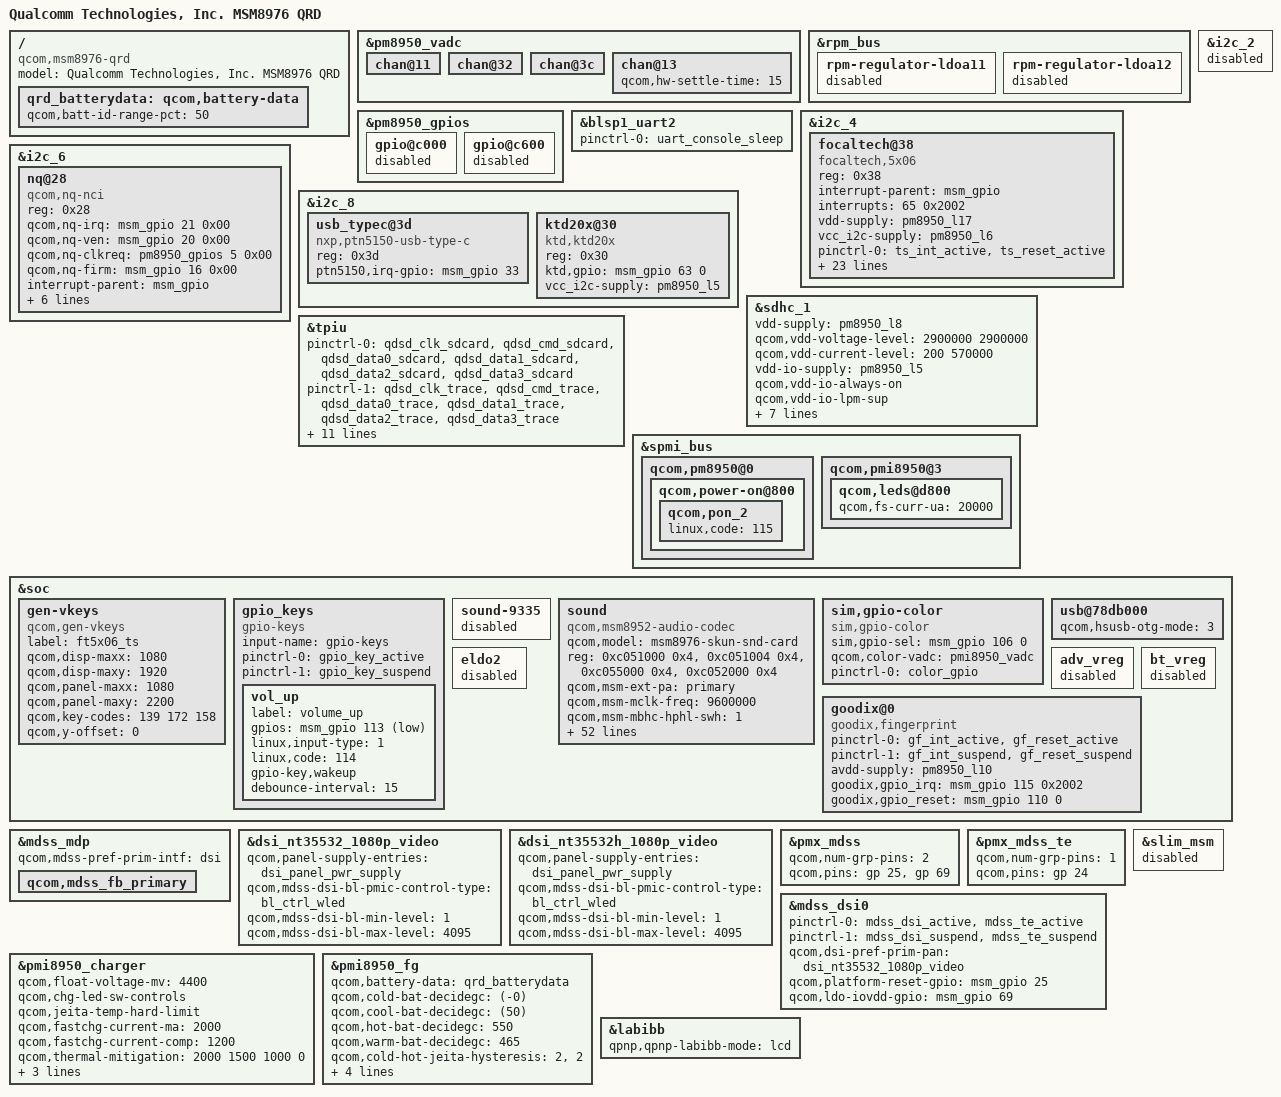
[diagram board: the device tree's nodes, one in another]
/*
 * Copyright (c) 2015, The Linux Foundation. All rights reserved.
 *
 * This program is free software; you can redistribute it and/or modify
 * it under the terms of the GNU General Public License version 2 and
 * only version 2 as published by the Free Software Foundation.
 *
 * This program is distributed in the hope that it will be useful,
 * but WITHOUT ANY WARRANTY; without even the implied warranty of
 * MERCHANTABILITY or FITNESS FOR A PARTICULAR PURPOSE.  See the
 * GNU General Public License for more details.
 */

#include "msm8976-camera-sensor-qrd.dtsi"

/ {
	model = "Qualcomm Technologies, Inc. MSM8976 QRD";
	compatible = "qcom,msm8976-qrd", "qcom,msm8976", "qcom,qrd";
};

&pm8950_vadc {
	chan@11 {
		/delete-property/ qcom,vadc-thermal-node;
	};
	chan@32 {
		/delete-property/ qcom,vadc-thermal-node;
	};
	chan@3c {
		/delete-property/ qcom,vadc-thermal-node;
	};
	chan@13 {
		/delete-property/ qcom,vadc-thermal-node;
	};
};

&rpm_bus {
	rpm-regulator-ldoa11 {
                status = "disabled";
	};

	rpm-regulator-ldoa12 {
                status = "disabled";
	};
};

&pm8950_gpios {
	gpio@c000 {
		status = "disabled";
	};

	gpio@c600 {
		status = "disabled";
	};
};

&pm8950_vadc {
	chan@13 {
		qcom,hw-settle-time = <15>;
	};
};

&blsp1_uart2 {
	status = "ok";
	pinctrl-names = "default";
	pinctrl-0 = <&uart_console_sleep>;
};

&i2c_2 { /* BLSP1 QUP2 */
	status = "disabled";
};

&i2c_4 { /* BLSP1 QUP4 */
        focaltech@38 {
                compatible = "focaltech,5x06";
                reg = <0x38>;
                interrupt-parent = <&msm_gpio>;
                interrupts = <65 0x2002>;
                vdd-supply = <&pm8950_l17>;
                vcc_i2c-supply = <&pm8950_l6>;
                /* pins used by touchscreen */
                pinctrl-names = "pmx_ts_active","pmx_ts_suspend","pmx_ts_release";
                pinctrl-0 = <&ts_int_active &ts_reset_active>;
                pinctrl-1 = <&ts_int_suspend &ts_reset_suspend>;
                pinctrl-2 = <&ts_release>;
                focaltech,name = "ft5336";
                focaltech,family-id = <0x06>;
                focaltech,reset-gpio = <&msm_gpio 64 0x0>;
                focaltech,irq-gpio = <&msm_gpio 65 0x2008>;
                focaltech,display-coords = <0 0 1080 1920>;
                focaltech,panel-coords = <0 0 1080 2200>;
                focaltech,button-map= <139 102 158>;
                focaltech,no-force-update;
                focaltech,i2c-pull-up;
                focaltech,group-id = <1>;
                focaltech,hard-reset-delay-ms = <20>;
                focaltech,soft-reset-delay-ms = <200>;
                focaltech,num-max-touches = <10>;
                focaltech,fw-delay-aa-ms = <30>;
                focaltech,fw-delay-55-ms = <30>;
                focaltech,fw-upgrade-id1 = <0x79>;
                focaltech,fw-upgrade-id2 = <0x08>;
                focaltech,fw-delay-readid-ms = <10>;
                focaltech,fw-delay-era-flsh-ms = <2000>;
                focaltech,fw-auto-cal;
                focaltech,ignore-id-check;
        };
};

&i2c_6 { /* BLSP2 QUP2 */
	nq@28 {
		compatible = "qcom,nq-nci";
		reg = <0x28>;
		qcom,nq-irq = <&msm_gpio 21 0x00>;
		qcom,nq-ven = <&msm_gpio 20 0x00>;
		qcom,nq-clkreq = <&pm8950_gpios 5 0x00>;
		qcom,nq-firm = <&msm_gpio 16 0x00>;
		interrupt-parent = <&msm_gpio>;
		qcom,clk-src = "BBCLK2";
		interrupts = <21 0>;
		interrupt-names = "nfc_irq";
		pinctrl-names = "nfc_active", "nfc_suspend";
		pinctrl-0 = <&nfc_int_active &nfc_disable_active>;
		pinctrl-1 = <&nfc_int_suspend &nfc_disable_suspend>;
		clocks = <&clock_gcc clk_bb_clk2_pin>;
		clock-names = "ref_clk";
	};
};

&i2c_8 { /* BLSP2 QUP4 */
	usb_typec@3d {
		compatible = "nxp,ptn5150-usb-type-c";
		reg = <0x3d>;
		ptn5150,irq-gpio = <&msm_gpio 33 0x2008>;
	};

        ktd20x@30 {
		compatible = "ktd,ktd20x";
		reg = <0x30>;
		ktd,gpio = <&msm_gpio 63 0>;
		vcc_i2c-supply = <&pm8950_l5>;
        };
};

&sdhc_1 {
	vdd-supply = <&pm8950_l8>;
	qcom,vdd-voltage-level = <2900000 2900000>;
	qcom,vdd-current-level = <200 570000>;

	vdd-io-supply = <&pm8950_l5>;
	qcom,vdd-io-always-on;
	qcom,vdd-io-lpm-sup;
	qcom,vdd-io-voltage-level = <1800000 1800000>;
	qcom,vdd-io-current-level = <200 325000>;

	pinctrl-names = "active", "sleep";
	pinctrl-0 = <&sdc1_clk_on &sdc1_cmd_on &sdc1_data_on &sdc1_rclk_on>;
	pinctrl-1 = <&sdc1_clk_off &sdc1_cmd_off &sdc1_data_off &sdc1_rclk_off>;

	qcom,nonremovable;

	status = "ok";
};

/* CoreSight */
&tpiu {
	pinctrl-names = "sdcard", "trace", "swduart",
			"swdtrc", "jtag", "spmi";
	/* NIDnT */
	pinctrl-0 = <&qdsd_clk_sdcard &qdsd_cmd_sdcard
		     &qdsd_data0_sdcard &qdsd_data1_sdcard
		     &qdsd_data2_sdcard &qdsd_data3_sdcard>;
	pinctrl-1 = <&qdsd_clk_trace &qdsd_cmd_trace
		     &qdsd_data0_trace &qdsd_data1_trace
		     &qdsd_data2_trace &qdsd_data3_trace>;
	pinctrl-2 = <&qdsd_cmd_swduart &qdsd_data0_swduart
		     &qdsd_data1_swduart &qdsd_data2_swduart
		     &qdsd_data3_swduart>;
	pinctrl-3 = <&qdsd_clk_swdtrc &qdsd_cmd_swdtrc
		     &qdsd_data0_swdtrc &qdsd_data1_swdtrc
		     &qdsd_data2_swdtrc &qdsd_data3_swdtrc>;
	pinctrl-4 = <&qdsd_cmd_jtag &qdsd_data0_jtag
		     &qdsd_data1_jtag &qdsd_data2_jtag
		     &qdsd_data3_jtag>;
	pinctrl-5 = <&qdsd_clk_spmi &qdsd_cmd_spmi
		     &qdsd_data0_spmi &qdsd_data3_spmi>;
};

&spmi_bus{
	qcom,pm8950@0 {
		qcom,power-on@800 {
			qcom,pon_2 {
				linux,code = <115>;
			};
		};
	};
	qcom,pmi8950@3 {
		qcom,leds@d800 {
			qcom,fs-curr-ua = <20000>;
		};
	};
};

&soc {

        gen-vkeys {
                compatible = "qcom,gen-vkeys";
                label = "ft5x06_ts";
                qcom,disp-maxx = <1080>;
                qcom,disp-maxy = <1920>;
                qcom,panel-maxx = <1080>;
                qcom,panel-maxy = <2200>;
                qcom,key-codes = <139 172 158>;
                qcom,y-offset = <0>;
        };

        gpio_keys {
                compatible = "gpio-keys";
                input-name = "gpio-keys";
                pinctrl-names = "tlmm_gpio_key_active","tlmm_gpio_key_suspend";
                pinctrl-0 = <&gpio_key_active>;
                pinctrl-1 = <&gpio_key_suspend>;

                vol_up {
                        label = "volume_up";
                        gpios = <&msm_gpio 113 0x1>;
                        linux,input-type = <1>;
                        linux,code = <114>;
                        gpio-key,wakeup;
                        debounce-interval = <15>;
                };
        };

        sound-9335 {
                status = "disabled";
        };

        sound {
                compatible = "qcom,msm8952-audio-codec";
                qcom,model = "msm8976-skun-snd-card";
                reg = <0xc051000 0x4>,
                      <0xc051004 0x4>,
                      <0xc055000 0x4>,
                      <0xc052000 0x4>;
                reg-names = "csr_gp_io_mux_mic_ctl",
                            "csr_gp_io_mux_spkr_ctl",
                            "csr_gp_io_lpaif_pri_pcm_pri_mode_muxsel",
                            "csr_gp_io_mux_quin_ctl";

                qcom,msm-ext-pa = "primary";
                qcom,msm-mclk-freq = <9600000>;
                qcom,msm-mbhc-hphl-swh = <1>;
                qcom,msm-mbhc-gnd-swh = <0>;
                qcom,msm-hs-micbias-type = "internal";
                qcom,msm-micbias1-ext-cap;
                qcom,audio-routing =
                        "RX_BIAS", "MCLK",
                        "SPK_RX_BIAS", "MCLK",
                        "INT_LDO_H", "MCLK",
                        "MIC BIAS External", "Handset Mic",
                        "MIC BIAS Internal2", "Headset Mic",
                        "MIC BIAS External", "Secondary Mic",
                        "AMIC1", "MIC BIAS External",
                        "AMIC2", "MIC BIAS Internal2",
                        "AMIC3", "MIC BIAS External";
                qcom,msm-gpios =
                        "pri_i2s";
                qcom,pinctrl-names =
                        "all_off",
                        "pri_i2s_act";
                pinctrl-names =
                        "all_off",
                        "pri_i2s_act";
                pinctrl-0 = <&cdc_pdm_lines_sus &cdc_pdm_lines_2_sus>;
                pinctrl-1 = <&cdc_pdm_lines_act &cdc_pdm_lines_2_act>;
                asoc-platform = <&pcm0>, <&pcm1>, <&pcm2>, <&voip>, <&voice>,
                                <&loopback>, <&compress>, <&hostless>,
                                <&afe>, <&lsm>, <&routing>, <&lpa>,
                                <&voice_svc>;
                asoc-platform-names = "msm-pcm-dsp.0", "msm-pcm-dsp.1",
                                "msm-pcm-dsp.2", "msm-voip-dsp",
                                "msm-pcm-voice", "msm-pcm-loopback",
                                "msm-compress-dsp", "msm-pcm-hostless",
                                "msm-pcm-afe", "msm-lsm-client",
                                "msm-pcm-routing", "msm-pcm-lpa",
                                "msm-voice-svc";
                asoc-cpu = <&dai_pri_auxpcm>, <&dai_hdmi>,
                                <&dai_mi2s0>, <&dai_mi2s1>, <&dai_mi2s2>,
                                <&dai_mi2s3>, <&dai_mi2s5>, <&dai_mi2s6>,
                                <&sb_0_rx>, <&sb_0_tx>, <&sb_1_rx>, <&sb_1_tx>,
                                <&sb_3_rx>, <&sb_3_tx>, <&sb_4_rx>, <&sb_4_tx>,
                                <&bt_sco_rx>, <&bt_sco_tx>, <&int_fm_rx>,
                                <&int_fm_tx>, <&afe_pcm_rx>, <&afe_pcm_tx>,
                                <&afe_proxy_rx>, <&afe_proxy_tx>,
                                <&incall_record_rx>, <&incall_record_tx>,
                                <&incall_music_rx>, <&incall_music_2_rx>;
                asoc-cpu-names = "msm-dai-q6-auxpcm.1", "msm-dai-q6-hdmi.8",
                                "msm-dai-q6-mi2s.0", "msm-dai-q6-mi2s.1",
                                "msm-dai-q6-mi2s.2", "msm-dai-q6-mi2s.3",
                                "msm-dai-q6-mi2s.5", "msm-dai-q6-mi2s.6",
                                "msm-dai-q6-dev.16384", "msm-dai-q6-dev.16385",
                                "msm-dai-q6-dev.16386", "msm-dai-q6-dev.16387",
                                "msm-dai-q6-dev.16390", "msm-dai-q6-dev.16391",
                                "msm-dai-q6-dev.16392", "msm-dai-q6-dev.16393",
                                "msm-dai-q6-dev.12288", "msm-dai-q6-dev.12289",
                                "msm-dai-q6-dev.12292", "msm-dai-q6-dev.12293",
                                "msm-dai-q6-dev.224", "msm-dai-q6-dev.225",
                                "msm-dai-q6-dev.241", "msm-dai-q6-dev.240",
                                "msm-dai-q6-dev.32771", "msm-dai-q6-dev.32772",
                                "msm-dai-q6-dev.32773", "msm-dai-q6-dev.32770";
                asoc-codec = <&stub_codec>, <&pm8950_cajon_dig>;
                asoc-codec-names = "msm-stub-codec.1", "cajon_codec";
        };

	sim,gpio-color {
                compatible = "sim,gpio-color";
                sim,gpio-sel = <&msm_gpio 106 0>;
                qcom,color-vadc = <&pmi8950_vadc>;

                pinctrl-names = "default";
                pinctrl-0 = <&color_gpio>;
        };
/* Disable following node as gpio-63 node would be controlled from KTD driver */
/*
        gpio-leds {
                compatible = "gpio-leds";
                status = "okay";

                disable_usb_led {
                        gpios = <&msm_gpio 63 0>;
                        label = "disable_usb_led";
                        linux,default-trigger = "default-on";
                        qcom,default-state = "on";
                        retain-state-suspended;
                };
        };
*/
        usb@78db000 {
                qcom,hsusb-otg-mode = <3>;/*Peripheral or Host mode */
        };

	eldo2 {
		status = "disabled";
	};

	adv_vreg {
		status = "disabled";
	};

	bt_vreg {
		status = "disabled";
	};
};

&soc {
        goodix@0 {
                compatible = "goodix,fingerprint";
                pinctrl-names = "pmx_gf_active", "pmx_gf_suspend";
                pinctrl-0 = <&gf_int_active &gf_reset_active>;
                pinctrl-1 = <&gf_int_suspend &gf_reset_suspend>;
                avdd-supply = <&pm8950_l10>;
                goodix,gpio_irq = <&msm_gpio 115 0x2002>;
                goodix,gpio_reset = <&msm_gpio 110 0>;
        };
};

#include "dsi-panel-nt35532-1080p-video.dtsi"
#include "dsi-panel-nt35532h-1080p-video.dtsi"

&mdss_mdp {
        qcom,mdss-pref-prim-intf = "dsi";
	qcom,mdss_fb_primary {
		/delete-property/ qcom,mdss-fb-splash-logo-enabled;
	};
};

&dsi_nt35532_1080p_video {
        qcom,panel-supply-entries = <&dsi_panel_pwr_supply>;
        qcom,mdss-dsi-bl-pmic-control-type = "bl_ctrl_wled";
        qcom,mdss-dsi-bl-min-level = <1>;
        qcom,mdss-dsi-bl-max-level = <4095>;
        //qcom,esd-check-enabled;
};

&dsi_nt35532h_1080p_video {
        qcom,panel-supply-entries = <&dsi_panel_pwr_supply>;
        qcom,mdss-dsi-bl-pmic-control-type = "bl_ctrl_wled";
        qcom,mdss-dsi-bl-min-level = <1>;
        qcom,mdss-dsi-bl-max-level = <4095>;
        //qcom,esd-check-enabled;
};

&pmx_mdss {
        qcom,num-grp-pins = <2>;
        qcom,pins = <&gp 25>, <&gp 69>;
};

&pmx_mdss_te {
        qcom,num-grp-pins = <1>;
        qcom,pins = <&gp 24>;
};

&mdss_dsi0 {
        pinctrl-names = "mdss_default", "mdss_sleep";
        pinctrl-0 = <&mdss_dsi_active &mdss_te_active>;
        pinctrl-1 = <&mdss_dsi_suspend &mdss_te_suspend>;
        qcom,dsi-pref-prim-pan = <&dsi_nt35532_1080p_video>;

        qcom,platform-reset-gpio = <&msm_gpio 25 0>;
        qcom,ldo-iovdd-gpio = <&msm_gpio 69 0>;
};


&pmi8950_charger {
        qcom,float-voltage-mv = <4400>;
        qcom,chg-led-sw-controls;
        /delete-property/ qcom,chg-led-support;
        qcom,jeita-temp-hard-limit;
        /delete-property/ qcom,parallel-usb-min-current-ma;
        /delete-property/ qcom,parallel-usb-9v-min-current-ma;
        /delete-property/ qcom,parallel-allowed-lowering-ma;
        qcom,fastchg-current-ma = <2000>;
        qcom,fastchg-current-comp = <1200>;
				qcom,thermal-mitigation = <2000 1500 1000 0>;
        qcom,charging-timeout-mins = <0>;
        qcom,precharging-timeout-mins = <0>;
        qcom,iterm-ma = <300>;
        status = "okay";
};

/ {
        qrd_batterydata: qcom,battery-data {
                qcom,batt-id-range-pct = <50>;
                #include "batterydata-phoenix-4v4-3025mah.dtsi"
        };
};

&pmi8950_fg {
        qcom,battery-data = <&qrd_batterydata>;
        qcom,cold-bat-decidegc = <(-0)>;
        qcom,cool-bat-decidegc = <(50)>;
        qcom,hot-bat-decidegc = <550>;
        qcom,warm-bat-decidegc = <465>;
        qcom,cold-hot-jeita-hysteresis = <2>, <2>;
        qcom,thermal-coefficients = [da 86 f0 50 08 3c];
        qcom,hold-soc-while-full;
        qcom,fp-chg-iterm-ma = <300>;
        qcom,fg-delta-soc = <1>;
};

&labibb {
        status = "ok";
        qpnp,qpnp-labibb-mode = "lcd";
};

&slim_msm {
        status = "disabled";
};

